# STM32F217 register map
File version: 1.1
CPU: CM3 r1p1, little endian, no MPU, no FPU, 4 interrupt priority bits
Registers are 32-bit, read-write, reset 0x0 unless marked. A register's access mark holds for its fields unless they carry their own. Offsets are from the block's base; [hi:lo] are bit positions; lines under a group give offsets from that group; {n}, {i} and the like mark numbered series.

## HASH — Hash processor
Base 0x50060400
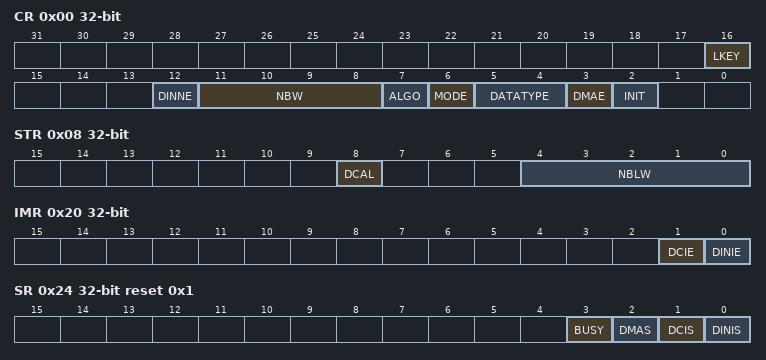
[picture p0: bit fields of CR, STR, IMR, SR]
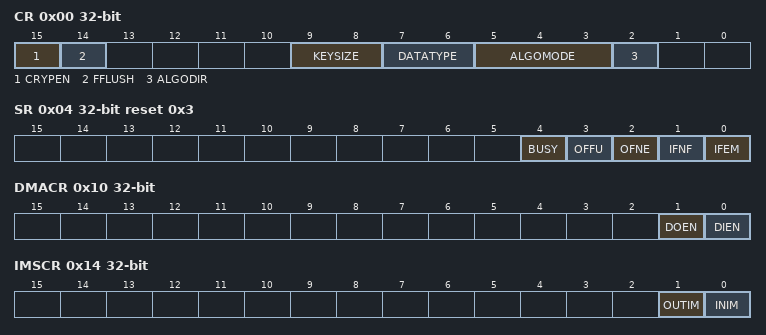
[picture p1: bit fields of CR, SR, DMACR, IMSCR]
0x00 CR access per field — control register
  [16] LKEY rw — Long key selection
  [12] DINNE ro — DIN not empty
  [11:8] NBW ro — Number of words already pushed
  [7] ALGO rw — Algorithm selection
  [6] MODE rw — Mode selection
  [5:4] DATATYPE rw — Data type selection
  [3] DMAE rw — DMA enable
  [2] INIT wo — Initialize message digest calculation
0x04 DIN — data input register
  [31:0] DATAIN — Data input
0x08 STR wo — start register
  [8] DCAL — Digest calculation
  [4:0] NBLW — Number of valid bits in the last word of the message
{0xC+4i} HR{i} (i=0..4) ro — digest registers
  [31:0] H — H0
0x20 IMR — interrupt enable register
  [1] DCIE — Digest calculation completion interrupt enable
  [0] DINIE — Data input interrupt enable
0x24 SR access per field reset 0x1 — status register
  [3] BUSY ro — Busy bit
  [2] DMAS ro — DMA Status
  [1] DCIS rw — Digest calculation completion interrupt status
  [0] DINIS rw — Data input interrupt status
{0xF8+4i} CSR{i} (i=0..50) — context swap registers
  [31:0] CSR — CSR0

## CRYP — Cryptographic processor
Base 0x50060000
0x00 CR access per field — control register
  [15] CRYPEN rw — Cryptographic processor enable
  [14] FFLUSH wo — FIFO flush
  [9:8] KEYSIZE rw — Key size selection (AES mode only)
  [7:6] DATATYPE rw — Data type selection
  [5:3] ALGOMODE rw — Algorithm mode
  [2] ALGODIR rw — Algorithm direction
0x04 SR ro reset 0x3 — status register
  [4] BUSY — Busy bit
  [3] OFFU — Output FIFO full
  [2] OFNE — Output FIFO not empty
  [1] IFNF — Input FIFO not full
  [0] IFEM — Input FIFO empty
0x08 DIN — data input register
  [31:0] DATAIN — Data input
0x0C DOUT ro — data output register
  [31:0] DATAOUT — Data output
0x10 DMACR — DMA control register
  [1] DOEN — DMA output enable
  [0] DIEN — DMA input enable
0x14 IMSCR — interrupt mask set/clear register
  [1] OUTIM — Output FIFO service interrupt mask
  [0] INIM — Input FIFO service interrupt mask
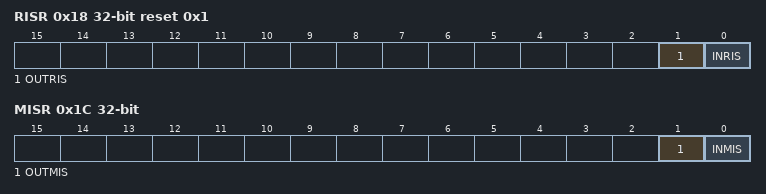
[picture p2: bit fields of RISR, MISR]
0x18 RISR ro reset 0x1 — raw interrupt status register
  [1] OUTRIS — Output FIFO service raw interrupt status
  [0] INRIS — Input FIFO service raw interrupt status
0x1C MISR ro — masked interrupt status register
  [1] OUTMIS — Output FIFO service masked interrupt status
  [0] INMIS — Input FIFO service masked interrupt status
{0x20+8i} KEY{i} (i=0..3) group — Cluster KEY{i}, containing K?LR, K?RR
  0x00 KLR wo — key registers
    [31:0] b2 — b224
  0x04 KRR wo — key registers
    [31:0] b — b192
{0x40+8i} INIT{i} (i=0..1) group — Cluster INIT{i}, containing IV?LR, IV?RR
  0x00 IVLR — initialization vector registers
    [31:0] IV — IV31
  0x04 IVRR — initialization vector registers
    [31:0] IV — IV63

## OTG_HS_HOST — USB on the go high speed
Base 0x40040400
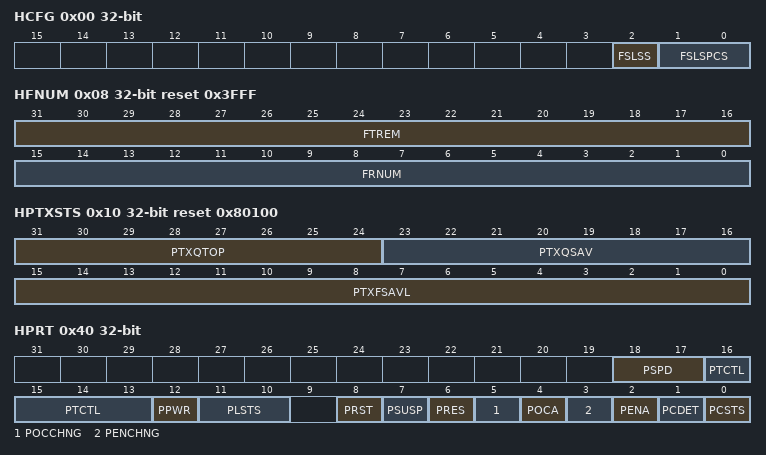
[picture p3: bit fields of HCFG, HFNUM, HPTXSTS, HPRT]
0x00 HCFG access per field — OTG_HS host configuration register
  [2] FSLSS ro — FS- and LS-only support
  [1:0] FSLSPCS rw — FS/LS PHY clock select
0x04 HFIR reset 0xEA60 — OTG_HS Host frame interval register
  [15:0] FRIVL — Frame interval
0x08 HFNUM ro reset 0x3FFF — OTG_HS host frame number/frame time remaining register
  [31:16] FTREM — Frame time remaining
  [15:0] FRNUM — Frame number
0x10 HPTXSTS access per field reset 0x80100 — OTG_HS_Host periodic transmit FIFO/queue status register
  [31:24] PTXQTOP ro — Top of the periodic transmit request queue
  [23:16] PTXQSAV ro — Periodic transmit request queue space available
  [15:0] PTXFSAVL rw — Periodic transmit data FIFO space available
0x14 HAINT ro — OTG_HS Host all channels interrupt register
  [15:0] HAINT — Channel interrupts
0x18 HAINTMSK — OTG_HS host all channels interrupt mask register
  [15:0] HAINTM — Channel interrupt mask
0x40 HPRT access per field — OTG_HS host port control and status register
  [18:17] PSPD ro — Port speed
  [16:13] PTCTL rw — Port test control
  [12] PPWR rw — Port power
  [11:10] PLSTS ro — Port line status
  [8] PRST rw — Port reset
  [7] PSUSP rw — Port suspend
  [6] PRES rw — Port resume
  [5] POCCHNG rw — Port overcurrent change
  [4] POCA ro — Port overcurrent active
  [3] PENCHNG rw — Port enable/disable change
  [2] PENA rw — Port enable
  [1] PCDET rw — Port connect detected
  [0] PCSTS ro — Port connect status
{0x100+0x20*i} HC{i} (i=0..11) group — Host channel
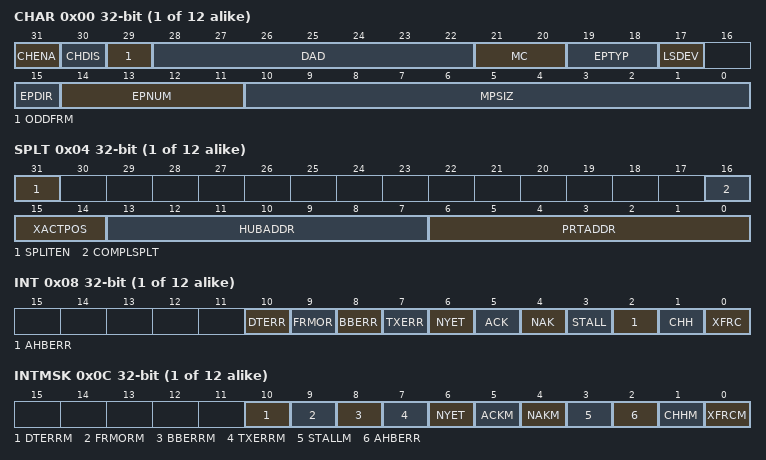
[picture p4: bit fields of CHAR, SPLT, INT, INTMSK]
  0x00 CHAR — OTG_HS host channel-0 characteristics register
    [31] CHENA — Channel enable
    [30] CHDIS — Channel disable
    [29] ODDFRM — Odd frame
    [28:22] DAD — Device address
    [21:20] MC — Multi Count (MC) / Error Count (EC)
    [19:18] EPTYP — Endpoint type
    [17] LSDEV — Low-speed device
    [15] EPDIR — Endpoint direction
    [14:11] EPNUM — Endpoint number
    [10:0] MPSIZ — Maximum packet size
  0x04 SPLT — OTG_HS host channel-0 split control register
    [31] SPLITEN — Split enable
    [16] COMPLSPLT — Do complete split
    [15:14] XACTPOS
    [13:7] HUBADDR — Hub address
    [6:0] PRTADDR — Port address
  0x08 INT — OTG_HS host channel-11 interrupt register
    [10] DTERR — Data toggle error
    [9] FRMOR — Frame overrun
    [8] BBERR — Babble error
    [7] TXERR — Transaction error
    [6] NYET — Response received interrupt
    [5] ACK — ACK response received/transmitted interrupt
    [4] NAK — NAK response received interrupt
    [3] STALL — STALL response received interrupt
    [2] AHBERR — AHB error
    [1] CHH — Channel halted
    [0] XFRC — Transfer completed
  0x0C INTMSK — OTG_HS host channel-11 interrupt mask register
    [10] DTERRM — Data toggle error mask
    [9] FRMORM — Frame overrun mask
    [8] BBERRM — Babble error mask
    [7] TXERRM — Transaction error mask
    [6] NYET — response received interrupt mask
    [5] ACKM — ACK response received/transmitted interrupt mask
    [4] NAKM — NAK response received interrupt mask
    [3] STALLM — STALL response received interrupt mask
    [2] AHBERR — AHB error
    [1] CHHM — Channel halted mask
    [0] XFRCM — Transfer completed mask
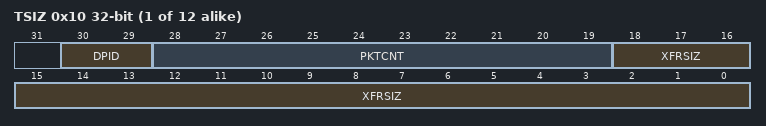
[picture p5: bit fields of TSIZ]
  0x10 TSIZ — OTG_HS host channel-11 transfer size register
    [30:29] DPID — Data PID
    [28:19] PKTCNT — Packet count
    [18:0] XFRSIZ — Transfer size
  0x14 DMA — OTG_HS host channel-0 DMA address register
    [31:0] DMAADDR — DMA address

## OTG_HS_PWRCLK — USB on the go high speed
Base 0x40040E00
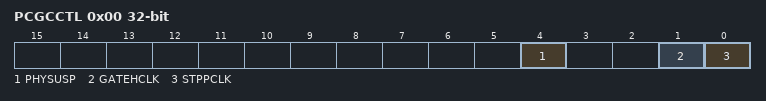
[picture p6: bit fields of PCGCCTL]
0x00 PCGCCTL — Power and clock gating control register
  [4] PHYSUSP — PHY suspended
  [1] GATEHCLK
  [0] STPPCLK — Stop PHY clock

## MPU — Memory protection unit
Base 0xE000ED90
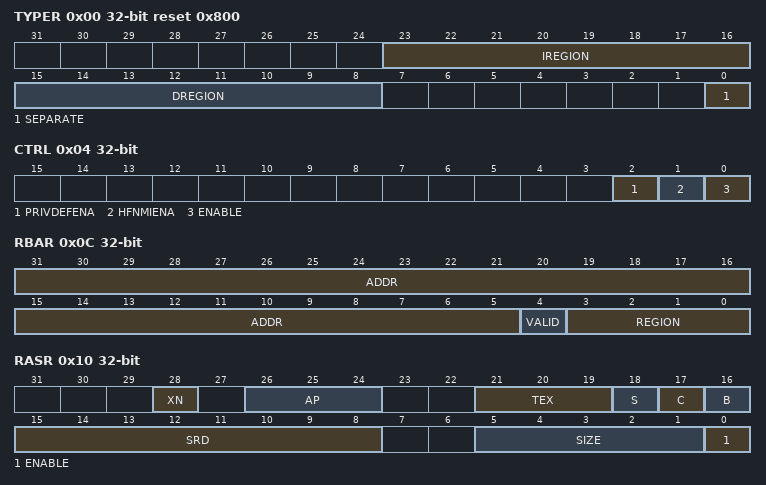
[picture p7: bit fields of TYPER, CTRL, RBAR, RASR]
0x00 TYPER ro reset 0x800 — MPU type register
  [23:16] IREGION — Number of MPU instruction regions
  [15:8] DREGION — Number of MPU data regions
  [0] SEPARATE — Separate flag
0x04 CTRL ro — MPU control register
  [2] PRIVDEFENA — Enable priviliged software access to default memory map
  [1] HFNMIENA — Enables the operation of MPU during hard fault
  [0] ENABLE — Enables the MPU
0x08 RNR — MPU region number register
  [7:0] REGION — MPU region
0x0C RBAR — MPU region base address register
  [31:5] ADDR — Region base address field
  [4] VALID — MPU region number valid
  [3:0] REGION — MPU region field
0x10 RASR — MPU region attribute and size register
  [28] XN — Instruction access disable bit
  [26:24] AP — Access permission
  [21:19] TEX — memory attribute
  [18] S — Shareable memory attribute
  [17] C — memory attribute
  [16] B — memory attribute
  [15:8] SRD — Subregion disable bits
  [5:1] SIZE — Size of the MPU protection region
  [0] ENABLE — Region enable bit.

## SCB_ACTRL — System control block ACTLR
Base 0xE000E008
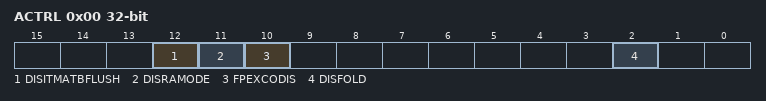
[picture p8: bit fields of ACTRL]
0x00 ACTRL — Auxiliary control register
  [12] DISITMATBFLUSH, [11] DISRAMODE, [10] FPEXCODIS, [2] DISFOLD

## NVIC_STIR — Nested vectored interrupt controller
Base 0xE000EF00
0x00 STIR — Software trigger interrupt register
  [8:0] INTID — Software generated interrupt ID

## STK — SysTick timer
Base 0xE000E010
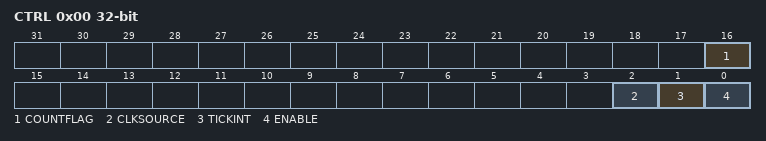
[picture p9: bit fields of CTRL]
0x00 CTRL — SysTick control and status register
  [16] COUNTFLAG
  [2] CLKSOURCE — Clock source selection
  [1] TICKINT — SysTick exception request enable
  [0] ENABLE — Counter enable
0x04 LOAD_ — SysTick reload value register
  [23:0] RELOAD — RELOAD value
0x08 VAL — SysTick current value register
  [23:0] CURRENT — Current counter value
0x0C CALIB — SysTick calibration value register
  [23:0] TENMS — Calibration value

## NVIC — Nested Vectored Interrupt Controller
Base 0xE000E100
{0x0+4i} ISER{i} (i=0..2) — Interrupt Set-Enable Register
  [31:0] SETENA
{0x80+4i} ICER{i} (i=0..2) — Interrupt Clear-Enable Register
  [31:0] CLRENA
{0x100+4i} ISPR{i} (i=0..2) — Interrupt Set-Pending Register
  [31:0] SETPEND
{0x180+4i} ICPR{i} (i=0..2) — Interrupt Clear-Pending Register
  [31:0] CLRPEND
{0x200+4i} IABR{i} ro (i=0..2) — Interrupt Active Bit Register
  [31:0] ACTIVE
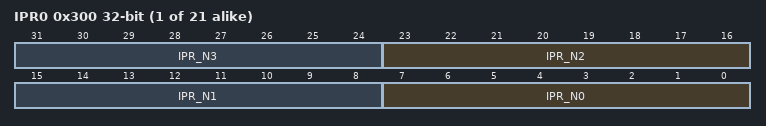
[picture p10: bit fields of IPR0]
{0x300+4i} IPR{i} (i=0..20) — Interrupt Priority Register
  [8n+7:8n] IPR_N{n} (n=0..3)
